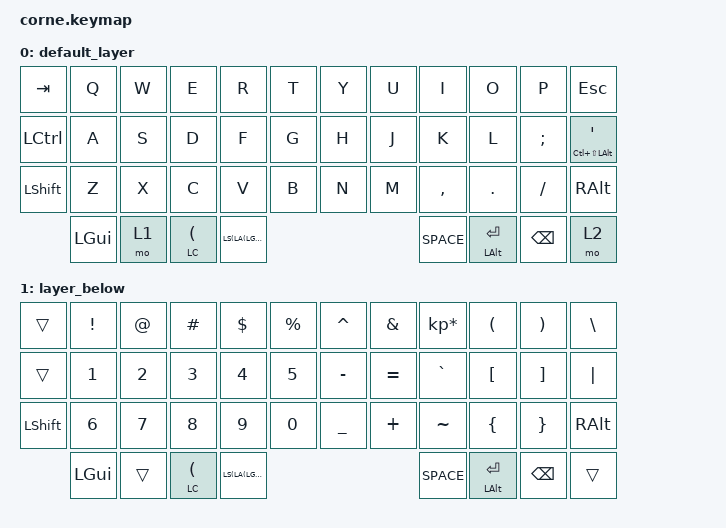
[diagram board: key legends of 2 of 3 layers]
/*
 * Copyright (c) 2020 The ZMK Contributors
 *
 * SPDX-License-Identifier: MIT
 */

#include <behaviors.dtsi>
#include <dt-bindings/zmk/keys.h>
#include <dt-bindings/zmk/bt.h>
#include <dt-bindings/zmk/ext_power.h>


/ {
        behaviors {
          tp: tap_preferred {
            compatible = "zmk,behavior-hold-tap";
            label = "TAP_PREFERRED";
            #binding-cells = <2>;
            tapping-term-ms = <150>;
            quick-tap-ms = <0>;
            flavor = "tap-preferred";
            bindings = <&kp>, <&kp>;
          }; 
        };

        keymap {
                compatible = "zmk,keymap";

                default_layer {
// -----------------------------------------------------------------------------------------
// | TAB  |  Q  |  W  |  E  |  R  |    T    |   |  Y  |  U   |  I  |  O  |  P  | ESC |
// | CTRL |  A  |  S  |  D  |  F  |    G    |   |  H  |  J   |  K  |  L  |  ;  |  '   |
// | SHFT |  Z  |  X  |  C  |  V  |    B    |   |  N  |  M   |  ,  |  .  |  /  | RALT |
//                    | GUI | LWR | ALT/ENT |   | HYPER/SPC | BKSP  | RSE |
                        bindings = <
   &kp TAB   &kp Q &kp W &kp E &kp R &kp T   &kp Y &kp U  &kp I     &kp O   &kp P    &kp ESC
   &kp LCTRL &kp A &kp S &kp D &kp F &kp G   &kp H &kp J  &kp K     &kp L   &kp SEMI &tp LC(LS(LALT)) SQT
   &kp LSHFT &kp Z &kp X &kp C &kp V &kp B   &kp N &kp M  &kp COMMA &kp DOT &kp FSLH &kp RALT 
               &kp LGUI &mo 1 &tp LC(LS(LA(LGUI))) SPACE  &tp LALT RET  &kp BSPC &mo 2
                        >;
                };

                layer_below {
// -----------------------------------------------------------------------------------------
// |      |  !  |  @  |  #  |  $  |    %     |   |  ^  |  &  |  *  |  (  |  )  |   \   |
// |      |  1  |  2  |  3  |  4  |    5     |   |  -  |  =  |  `  |  [  |  ]  |  "|"  |
// | SHFT |  6  |  7  |  8  |  9  |    0     |   |  _  |  +  |  ~  |  {  |  }  | RALT |
//                     | GUI |     | ALT/ENT |   | HYPER/SPACE | BKSP |    |
                        bindings = <
   &trans    &kp EXCL &kp AT &kp HASH &kp DLLR &kp PRCNT   &kp CARET  &kp AMPS  &kp KP_MULTIPLY &kp LPAR &kp RPAR &kp BSLH
   &trans    &kp N1   &kp N2 &kp N3   &kp N4   &kp N5      &kp MINUS  &kp EQUAL &kp GRAVE       &kp LBKT &kp RBKT &kp PIPE
   &kp LSHFT &kp N6   &kp N7 &kp N8   &kp N9   &kp N0      &kp UNDER  &kp PLUS  &kp TILDE       &kp LBRC &kp RBRC &kp RALT
                         &kp LGUI &trans       &tp LC(LS(LA(LGUI))) SPACE  &tp LALT RET &kp BSPC  &trans
                        >;
                };

                layer_above {
// -----------------------------------------------------------------------------------------
// |       |  F1  |  F2  |  F3  |  F4  |  F5 |            |  F6  |  F7  |  F8  |  F9  |  F10  |   |
// |       | Prev | Next | Vol - | Vol + | Play/Pause |   |      | LFT | DWN |  UP | RGT |     |     |
// | BTCLR | BT1 | BT2 | BT3 | BT4 | BT5 |   |            | EP_ON |   |     |     |     |  EP_OFF   |
//                    |     |     |    |                  |     |     |     |
                        bindings = <
   &trans     &kp F1        &kp F2       &kp F3       &kp F4       &kp F5          &kp F6   &kp F7   &kp F8 &kp F9    &kp F10 &trans
   &trans     &kp K_PREV    &kp K_NEXT   &kp C_VOL_DN &kp C_VOL_UP &kp C_PP        &kp LEFT &kp DOWN &kp UP &kp RIGHT &trans &trans
   &bt BT_CLR &bt BT_SEL 0  &bt BT_SEL 1 &bt BT_SEL 2 &bt BT_SEL 3 &bt BT_SEL 4    &ext_power EP_ON  &trans &trans    &trans &ext_power EP_OFF
                          	                        &trans   &trans   &trans       &trans   &trans   &trans
                        >;
                };
        };
};

